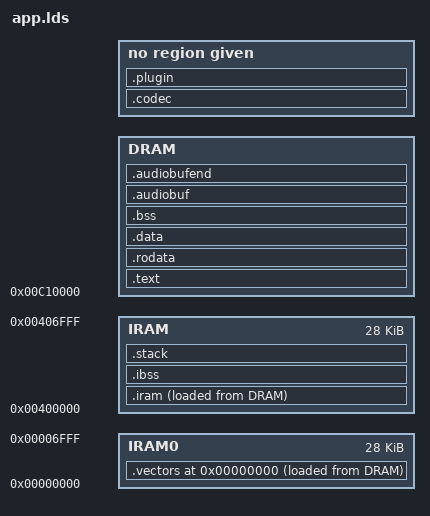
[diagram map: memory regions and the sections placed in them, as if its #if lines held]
#include "config.h"

ENTRY(start)

OUTPUT_FORMAT(elf32-littlearm)
OUTPUT_ARCH(arm)
STARTUP(target/arm/pnx0101/crt0-pnx0101.o)

#define PLUGINSIZE PLUGIN_BUFFER_SIZE
#define CODECSIZE CODEC_SIZE

#ifdef DEBUG
#define STUBOFFSET 0x10000
#else
#define STUBOFFSET 0
#endif

#define DRAMSIZE (MEMORYSIZE * 0x100000) - PLUGINSIZE - STUBOFFSET - CODECSIZE

#define DRAMORIG 0xc00000 + STUBOFFSET
#define IRAM0ORIG 0x000000
#define IRAM0SIZE 0x7000
#define IRAMORIG 0x400000
#define IRAMSIZE 0x7000

/* End of the audio buffer, where the codec buffer starts */
#define ENDAUDIOADDR  (DRAMORIG + DRAMSIZE)

/* Where the codec buffer ends, and the plugin buffer starts */
#define ENDADDR (ENDAUDIOADDR + CODECSIZE)

MEMORY
{
    DRAM : ORIGIN = DRAMORIG, LENGTH = DRAMSIZE
    IRAM : ORIGIN = IRAMORIG, LENGTH = IRAMSIZE
    IRAM0 : ORIGIN = IRAM0ORIG, LENGTH = IRAM0SIZE
}

SECTIONS
{
    .text :
    {
        loadaddress = .;
        _loadaddress = .;
        . = ALIGN(0x200);
        *(.init.text)
        *(.text*)
        *(.glue_7)
        *(.glue_7t)
        . = ALIGN(0x4);
    } > DRAM

    .rodata :
    {
        *(.rodata)  /* problems without this, dunno why */
        *(.rodata*)
        *(.rodata.str1.1)
        *(.rodata.str1.4)
        . = ALIGN(0x4);

        /* Pseudo-allocate the copies of the data sections */
        _datacopy = .;
    } > DRAM

    /* TRICK ALERT! For RAM execution, we put the .data section at the
       same load address as the copy. Thus, we don't waste extra RAM
       when we don't actually need the copy.  */
    .data : AT ( _datacopy )
    {
        _datastart = .;
        *(.data*)
        . = ALIGN(0x4);
        _dataend  = .;
    } > DRAM

    /DISCARD/ :
    {
        *(.eh_frame)
    }

    .vectors 0x0 :
    {
        _vectorsstart = .;
        *(.vectors);
        _vectorsend = .;
        *(.dmabuf)
    } >IRAM0 AT> DRAM

    _vectorscopy = LOADADDR(.vectors);

    .iram IRAMORIG + SIZEOF(.vectors) :
    {
        _iramstart = .;
        *(.icode)
        *(.irodata)
        *(.idata)
        . = ALIGN(0x4);
        _iramend = .;
    } > IRAM AT> DRAM

    _iramcopy = LOADADDR(.iram);

    .ibss (NOLOAD) :
    {
        _iedata = .;
        *(.ibss)
        . = ALIGN(0x4);
        _iend = .;
    } > IRAM

   .stack :
    {
       *(.stack)
       stackbegin = .;
       . += 0x2000;
       stackend = .;
    } > IRAM

    .bss ADDR(.data) + SIZEOF(.data) + SIZEOF(.iram) + SIZEOF(.vectors):
    {
       _edata = .;
        *(.bss*)
        *(COMMON)
        . = ALIGN(0x4);
       _end = .;
    } > DRAM

    .audiobuf ALIGN(4) :
    {
        _audiobuffer = .;
        audiobuffer = .;
    } > DRAM

    .audiobufend ENDAUDIOADDR:
    {
        audiobufend = .;
        _audiobufend = .;
    } > DRAM

    .codec ENDAUDIOADDR:
    {
        codecbuf = .;
        _codecbuf = .;
    }

    .plugin ENDADDR:
    {
        _pluginbuf = .;
        pluginbuf = .;
    }
}

